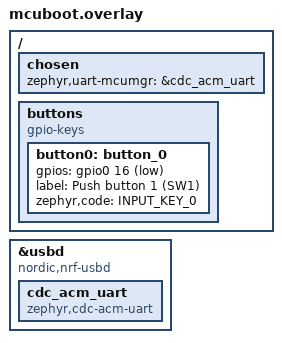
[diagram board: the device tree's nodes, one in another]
/ {
	chosen {
		zephyr,uart-mcumgr = &cdc_acm_uart;
	};


    // leds: leds {
	// 	compatible = "gpio-leds";
	// 	led0: led_0 {
	// 		gpios = <&gpio1 10 GPIO_ACTIVE_HIGH>;
	// 	};

	// };

	buttons {
		compatible = "gpio-keys";
		button0: button_0 {
			gpios = <&gpio0 16 (GPIO_PULL_UP | GPIO_ACTIVE_LOW)>;
			label = "Push button 1 (SW1)";
			zephyr,code = <INPUT_KEY_0>;
		};
	};
};

zephyr_udc0: &usbd {
	compatible = "nordic,nrf-usbd";
	status = "okay";

	cdc_acm_uart: cdc_acm_uart {
		compatible = "zephyr,cdc-acm-uart";
	};
};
